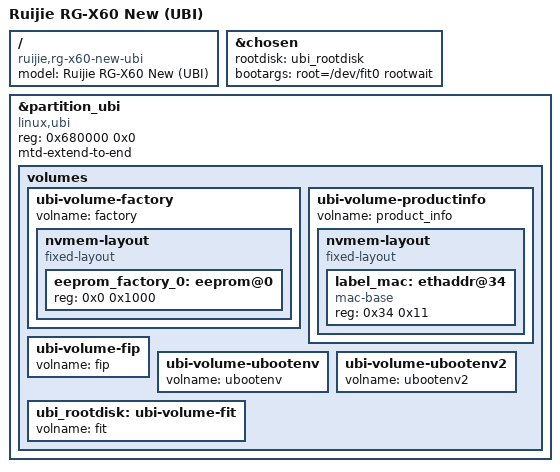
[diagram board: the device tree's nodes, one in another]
// SPDX-License-Identifier: (GPL-2.0 OR MIT)

/dts-v1/;
#include "mt7986a-ruijie-rg-x60-new-common.dtsi"

/ {
	model = "Ruijie RG-X60 New (UBI)";
	compatible = "ruijie,rg-x60-new-ubi", "mediatek,mt7986a";
};

&chosen {
	rootdisk = <&ubi_rootdisk>;
	bootargs = "root=/dev/fit0 rootwait";
};

&partition_ubi {
	compatible = "linux,ubi";
	reg = <0x680000 0x0>;
	mtd-extend-to-end;

	volumes {
		ubi-volume-factory {
			volname = "factory";

			nvmem-layout {
				compatible = "fixed-layout";
				#address-cells = <1>;
				#size-cells = <1>;
				
				eeprom_factory_0: eeprom@0 {
					reg = <0x0 0x1000>;
				};
			};
		};

		ubi-volume-productinfo {
			volname = "product_info";

			nvmem-layout {
				compatible = "fixed-layout";
				#address-cells = <1>;
				#size-cells = <1>;

				label_mac: ethaddr@34 {
					compatible = "mac-base";
					reg = <0x34 0x11>;
					#nvmem-cell-cells = <1>;
				};
			};
		};

		ubi-volume-fip {
			volname = "fip";
		};

		ubi-volume-ubootenv {
			volname = "ubootenv";
		};

		ubi-volume-ubootenv2 {
			volname = "ubootenv2";
		};

		ubi_rootdisk: ubi-volume-fit {
			volname = "fit";
		};
	};
};
